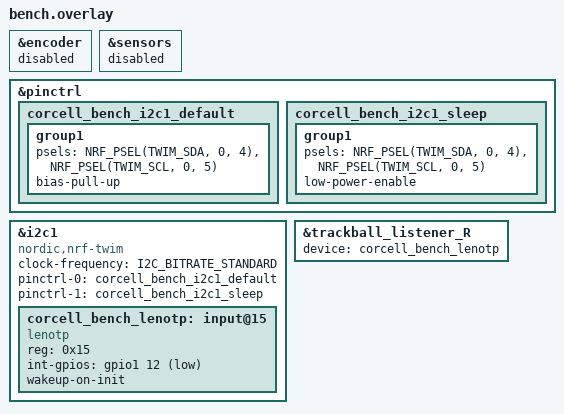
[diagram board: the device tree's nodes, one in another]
#include <dt-bindings/pinctrl/nrf-pinctrl.h>
#include <zephyr/dt-bindings/i2c/i2c.h>

/*
 * Bench build: prove a lenoTP module works, with nothing else in the way.
 *
 * The product wiring puts slot 1's I2C on P0.09/P0.10, which on a XIAO are
 * only reachable from the NFC pads on the back - awkward to hand-wire, and
 * they drag in both the NFC pin question and the i2c0/spi0 shared-instance
 * problem. This build moves the module onto the XIAO's own I2C pins, which
 * are ordinary castellated pads:
 *
 *   D4  P0.04  SDA
 *   D5  P0.05  SCL
 *   D7  P1.12  INT
 *   3V3        VCC
 *   GND        GND
 *
 * The rotary encoder shares D4/D5, so it is switched off here. That costs
 * nothing on the bench.
 */
&encoder {
    status = "disabled";
};

&sensors {
    status = "disabled";
};

&pinctrl {
    corcell_bench_i2c1_default: corcell_bench_i2c1_default {
        group1 {
            psels = <NRF_PSEL(TWIM_SDA, 0, 4)>,
                    <NRF_PSEL(TWIM_SCL, 0, 5)>;
            bias-pull-up;
        };
    };

    corcell_bench_i2c1_sleep: corcell_bench_i2c1_sleep {
        group1 {
            psels = <NRF_PSEL(TWIM_SDA, 0, 4)>,
                    <NRF_PSEL(TWIM_SCL, 0, 5)>;
            low-power-enable;
        };
    };
};

&i2c1 {
    compatible = "nordic,nrf-twim";
    status = "okay";
    clock-frequency = <I2C_BITRATE_STANDARD>;
    pinctrl-0 = <&corcell_bench_i2c1_default>;
    pinctrl-1 = <&corcell_bench_i2c1_sleep>;
    pinctrl-names = "default", "sleep";

    corcell_bench_lenotp: input@15 {
        compatible = "lenotp";
        reg = <0x15>;
        status = "okay";
        int-gpios = <&gpio1 12 (GPIO_ACTIVE_LOW | GPIO_PULL_UP)>;
        wakeup-on-init;
    };
};

&trackball_listener_R {
    status = "okay";
    device = <&corcell_bench_lenotp>;
};
